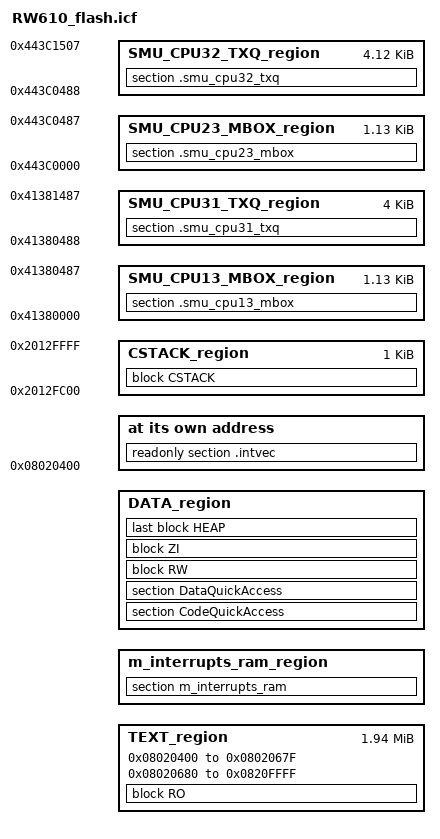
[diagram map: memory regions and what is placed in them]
/*
** ###################################################################
**     Processors:          RW612ETA1I
**                          RW612HNA1I
**                          RW612UKA1I
**
**     Compiler:            IAR ANSI C/C++ Compiler for ARM
**     Reference manual:    RW61X User manual Rev. 0.95, June 2022
**     Version:             rev. 1.0, 2021-03-16
**     Build:               b221116
**
**     Abstract:
**         Linker file for the IAR ANSI C/C++ Compiler for ARM
**
**     Copyright 2016 Freescale Semiconductor, Inc.
**     Copyright 2016-2022 NXP
**     All rights reserved.
**
**     SPDX-License-Identifier: BSD-3-Clause
**
**     http:                 www.nxp.com
**     mail:                 support@nxp.com
**
** ###################################################################
*/

/* Stack and Heap Sizes */
if (isdefinedsymbol(__stack_size__)) {
  define symbol __size_cstack__        = __stack_size__;
} else {
  define symbol __size_cstack__        = 0x0400;
}

if (isdefinedsymbol(__heap_size__)) {
  define symbol __size_heap__          = __heap_size__;
} else {
  define symbol __size_heap__          = 0x0400;
}

define symbol __ram_vector_table_size__        =  isdefinedsymbol(__ram_vector_table__) ? 0x00000280 : 0;
define symbol __ram_vector_table_offset__      =  isdefinedsymbol(__ram_vector_table__) ? 0x0000027F : 0;

define symbol m_interrupts_start               = 0x08020400;
define symbol m_interrupts_end                 = 0x0802067F;

define symbol m_text_start                     = 0x08020680;
define symbol m_text_end                       = 0x0820FFFF;

define symbol m_interrupts_ram_start           = 0x20000000;
define symbol m_interrupts_ram_end             = 0x20000000 + __ram_vector_table_offset__;

define symbol m_data_start                     = m_interrupts_ram_start + __ram_vector_table_size__;
define symbol m_data_end                       = 0x2012FFFF;

define symbol m_mbox1_start                    = 0x41380000;
define symbol m_mbox1_end                      = 0x41380487;

define symbol m_txq1_start                     = 0x41380488;
define symbol m_txq1_end                       = 0x41381487;

define symbol m_mbox2_start                    = 0x443C0000;
define symbol m_mbox2_end                      = 0x443C0487;

define symbol m_txq2_start                     = 0x443C0488;
define symbol m_txq2_end                       = 0x443C1507;

define exported symbol __VECTOR_TABLE          = m_interrupts_start;
define exported symbol __VECTOR_RAM            = isdefinedsymbol(__ram_vector_table__) ? m_interrupts_ram_start : m_interrupts_start;
define exported symbol __RAM_VECTOR_TABLE_SIZE = __ram_vector_table_size__;

define memory mem with size = 4G;

define region TEXT_region             = mem:[from m_interrupts_start to m_interrupts_end]
                                      | mem:[from m_text_start to m_text_end];
define region m_interrupts_ram_region = mem:[from m_interrupts_ram_start to m_interrupts_ram_end];
define region DATA_region             = mem:[from m_data_start to m_data_end - __size_cstack__];
define region CSTACK_region           = mem:[from m_data_end-__size_cstack__ + 1 to m_data_end];
define region SMU_CPU13_MBOX_region   = mem:[from m_mbox1_start to m_mbox1_end];
define region SMU_CPU31_TXQ_region    = mem:[from m_txq1_start to m_txq1_end];
define region SMU_CPU23_MBOX_region   = mem:[from m_mbox2_start to m_mbox2_end];
define region SMU_CPU32_TXQ_region    = mem:[from m_txq2_start to m_txq2_end];

define block CSTACK    with alignment = 8, size = __size_cstack__   { };
define block HEAP      with alignment = 8, size = __size_heap__     { };
define block RO        { readonly };
define block RW        { readwrite };
define block ZI        { zi };

initialize by copy {
  readwrite,
  /* Place in RAM flash and performance dependent functions  */
  readonly object fsl_flexspi.o,
  readonly object mflash_drv.o,
  section .textrw,
  section CodeQuickAccess,
  section DataQuickAccess
};

do not initialize  { section .noinit, section .smu_cpu13_mbox, section .smu_cpu31_txq, section .smu_cpu23_mbox, section .smu_cpu32_txq};

place at address mem: m_interrupts_start    { readonly section .intvec };
place in TEXT_region                        { block RO };
place in m_interrupts_ram_region            { section m_interrupts_ram };
place in DATA_region                        { section CodeQuickAccess, section DataQuickAccess };
place in DATA_region                        { block RW };
place in DATA_region                        { block ZI };
place in DATA_region                        { last block HEAP };
place in CSTACK_region                      { block CSTACK };
place in SMU_CPU13_MBOX_region              { section .smu_cpu13_mbox };
place in SMU_CPU31_TXQ_region               { section .smu_cpu31_txq };
place in SMU_CPU23_MBOX_region              { section .smu_cpu23_mbox };
place in SMU_CPU32_TXQ_region               { section .smu_cpu32_txq };
